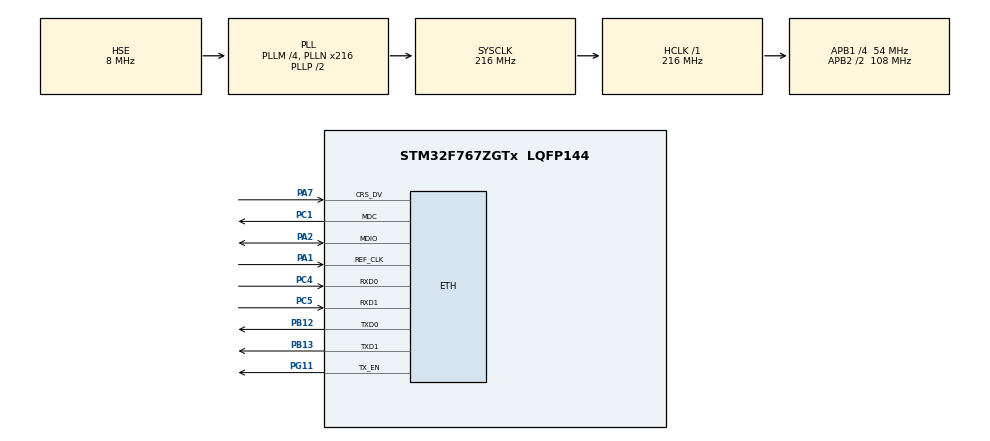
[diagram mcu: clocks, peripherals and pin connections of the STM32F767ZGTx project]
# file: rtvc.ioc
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ETH.MediaInterface=HAL_ETH_RMII_MODE
FREERTOS.Tasks01=defaultTask,0,512,StartDefaultTask,Default,NULL,Dynamic,NULL,NULL
FREERTOS.configMINIMAL_STACK_SIZE=512
LWIP.BSP.number=1
LWIP.GATEWAY_ADDRESS=010.000.000.050
LWIP.IP_ADDRESS=010.000.000.015
LWIP.LWIP_DHCP=0
LWIP.LWIP_RAM_HEAP_POINTER=0x20044000
LWIP.MEMP_NUM_TCP_SEG=17
LWIP.MEM_SIZE=16360
LWIP.NETMASK_ADDRESS=255.255.255.000
LWIP.TCP_MSS=1460
LWIP.TCP_SND_BUF=5840
LWIP.Version=v2.1.2_Cube
LWIP0.BSP.STBoard=false
LWIP0.BSP.api=BSP_COMPONENT_DRIVER
LWIP0.BSP.component=LAN8742
LWIP0.BSP.instance=LAN8742
LWIP0.BSP.name=Driver_PHY
LWIP0.BSP.semaphore=S_LAN8742
LWIP0.BSP.solution=LAN8742
Mcu.Family=STM32F7
Mcu.Name=STM32F767ZGTx
Mcu.Package=LQFP144
NVIC.ETH_IRQn=true\:5\:0\:false\:false\:true\:true\:false\:true\:true
NVIC.PriorityGroup=NVIC_PRIORITYGROUP_4
NVIC.TIM3_IRQn=true\:15\:0\:false\:false\:true\:false\:false\:true\:true
NVIC.TimeBase=TIM3_IRQn
NVIC.TimeBaseIP=TIM3
PA1.Mode=RMII
PA1.Signal=ETH_REF_CLK
PA13.Mode=JTAG_4_pins
PA13.Signal=SYS_JTMS-SWDIO
PA14.Mode=JTAG_4_pins
PA14.Signal=SYS_JTCK-SWCLK
PA15.Mode=JTAG_4_pins
PA15.Signal=SYS_JTDI
PA2.Mode=RMII
PA2.Signal=ETH_MDIO
PA7.Mode=RMII
PA7.Signal=ETH_CRS_DV
PB12.Mode=RMII
PB12.Signal=ETH_TXD0
PB13.Mode=RMII
PB13.Signal=ETH_TXD1
PB3.Mode=JTAG_4_pins
PB3.Signal=SYS_JTDO-SWO
PC1.Mode=RMII
PC1.Signal=ETH_MDC
PC4.Mode=RMII
PC4.Signal=ETH_RXD0
PC5.Mode=RMII
PC5.Signal=ETH_RXD1
PG11.Mode=RMII
PG11.Signal=ETH_TX_EN
PH0/OSC_IN.Mode=HSE-External-Oscillator
PH0/OSC_IN.Signal=RCC_OSC_IN
PH1/OSC_OUT.Mode=HSE-External-Oscillator
PH1/OSC_OUT.Signal=RCC_OSC_OUT
ProjectManager.HeapSize=0x200
ProjectManager.StackSize=0x400
ProjectManager.TargetToolchain=STM32CubeIDE
RCC.AHBFreq_Value=216000000
RCC.APB1CLKDivider=RCC_HCLK_DIV4
RCC.APB1Freq_Value=54000000
RCC.APB1TimFreq_Value=108000000
RCC.APB2CLKDivider=RCC_HCLK_DIV2
RCC.APB2Freq_Value=108000000
RCC.APB2TimFreq_Value=216000000
RCC.CortexFreq_Value=216000000
RCC.HCLKFreq_Value=216000000
RCC.HSE_VALUE=8000000
RCC.HSI_VALUE=16000000
RCC.LSE_VALUE=32768
RCC.PLLM=4
RCC.PLLN=216
RCC.PLLSourceVirtual=RCC_PLLSOURCE_HSE
RCC.SYSCLKFreq_VALUE=216000000
RCC.SYSCLKSource=RCC_SYSCLKSOURCE_PLLCLK
RCC.USBFreq_Value=216000000
RCC.VCOOutputFreq_Value=432000000
VP_FREERTOS_VS_CMSIS_V1.Mode=CMSIS_V1
VP_LWIP_VS_Enabled.Mode=Enabled
VP_SYS_VS_tim3.Mode=TIM3
board=custom

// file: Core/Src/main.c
/* USER CODE BEGIN Header */
/**
  ******************************************************************************
  * @file           : main.c
  * @brief          : Main program body
  ******************************************************************************
  * @attention
  *
  * Copyright (c) 2025 STMicroelectronics.
  * All rights reserved.
  *
  * This software is licensed under terms that can be found in the LICENSE file
  * in the root directory of this software component.
  * If no LICENSE file comes with this software, it is provided AS-IS.
  *
  ******************************************************************************
  */
/* USER CODE END Header */
#include "main.h"
#include "cmsis_os.h"
#include "lwip.h"

/* USER CODE BEGIN Includes */
#include "lan8742.h"
/* USER CODE END Includes */

osThreadId defaultTaskHandle;

void SystemClock_Config(void);
static void MX_GPIO_Init(void);
void StartDefaultTask(void const * argument);

int main(void)
{

  /* MCU Configuration--------------------------------------------------------*/

  /* Reset of all peripherals, Initializes the Flash interface and the Systick. */
  HAL_Init();

  /* Configure the system clock */
  SystemClock_Config();

  /* Initialize all configured peripherals */
  MX_GPIO_Init();

  /* Create the thread(s) */
  /* definition and creation of defaultTask */
  osThreadDef(defaultTask, StartDefaultTask, osPriorityNormal, 0, 512);
  defaultTaskHandle = osThreadCreate(osThread(defaultTask), NULL);

  /* Start scheduler */
  osKernelStart();

  /* We should never get here as control is now taken by the scheduler */

  /* Infinite loop */
  while (1)
  {

  }
}

void SystemClock_Config(void)
{
  RCC_OscInitTypeDef RCC_OscInitStruct = {0};
  RCC_ClkInitTypeDef RCC_ClkInitStruct = {0};

  /** Configure the main internal regulator output voltage
  */
  __HAL_RCC_PWR_CLK_ENABLE();
  __HAL_PWR_VOLTAGESCALING_CONFIG(PWR_REGULATOR_VOLTAGE_SCALE1);

  /** Initializes the RCC Oscillators according to the specified parameters
  * in the RCC_OscInitTypeDef structure.
  */
  RCC_OscInitStruct.OscillatorType = RCC_OSCILLATORTYPE_HSE;
  RCC_OscInitStruct.HSEState = RCC_HSE_ON;
  RCC_OscInitStruct.PLL.PLLState = RCC_PLL_ON;
  RCC_OscInitStruct.PLL.PLLSource = RCC_PLLSOURCE_HSE;
  RCC_OscInitStruct.PLL.PLLM = 4;
  RCC_OscInitStruct.PLL.PLLN = 216;
  RCC_OscInitStruct.PLL.PLLP = RCC_PLLP_DIV2;
  RCC_OscInitStruct.PLL.PLLQ = 2;
  RCC_OscInitStruct.PLL.PLLR = 2;
  if (HAL_RCC_OscConfig(&RCC_OscInitStruct) != HAL_OK)
  {
    Error_Handler();
  }

  /** Activate the Over-Drive mode
  */
  if (HAL_PWREx_EnableOverDrive() != HAL_OK)
  {
    Error_Handler();
  }

  /** Initializes the CPU, AHB and APB buses clocks
  */
  RCC_ClkInitStruct.ClockType = RCC_CLOCKTYPE_HCLK|RCC_CLOCKTYPE_SYSCLK
                              |RCC_CLOCKTYPE_PCLK1|RCC_CLOCKTYPE_PCLK2;
  RCC_ClkInitStruct.SYSCLKSource = RCC_SYSCLKSOURCE_PLLCLK;
  RCC_ClkInitStruct.AHBCLKDivider = RCC_SYSCLK_DIV1;
  RCC_ClkInitStruct.APB1CLKDivider = RCC_HCLK_DIV4;
  RCC_ClkInitStruct.APB2CLKDivider = RCC_HCLK_DIV2;

  if (HAL_RCC_ClockConfig(&RCC_ClkInitStruct, FLASH_LATENCY_7) != HAL_OK)
  {
    Error_Handler();
  }
}

static void MX_GPIO_Init(void)
{

  /* GPIO Ports Clock Enable */
  __HAL_RCC_GPIOH_CLK_ENABLE();
  __HAL_RCC_GPIOC_CLK_ENABLE();
  __HAL_RCC_GPIOA_CLK_ENABLE();
  __HAL_RCC_GPIOB_CLK_ENABLE();
  __HAL_RCC_GPIOG_CLK_ENABLE();

}

void StartDefaultTask(void const * argument)
{
  /* init code for LWIP */
  MX_LWIP_Init();
  /* USER CODE BEGIN 5 */
  /* Infinite loop */
  for(;;)
  {
    volatile int32_t status = LAN8742_GetLinkState(&LAN8742);
    osDelay(1000);
  }
  /* USER CODE END 5 */
}

void HAL_TIM_PeriodElapsedCallback(TIM_HandleTypeDef *htim)
{
  if (htim->Instance == TIM3) {
    HAL_IncTick();
  }
}

void Error_Handler(void)
{
  __disable_irq();
  while (1)
  {
  }
}

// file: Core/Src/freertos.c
/* USER CODE BEGIN Header */
/**
  ******************************************************************************
  * File Name          : freertos.c
  * Description        : Code for freertos applications
  ******************************************************************************
  * @attention
  *
  * Copyright (c) 2025 STMicroelectronics.
  * All rights reserved.
  *
  * This software is licensed under terms that can be found in the LICENSE file
  * in the root directory of this software component.
  * If no LICENSE file comes with this software, it is provided AS-IS.
  *
  ******************************************************************************
  */
/* USER CODE END Header */

#include "FreeRTOS.h"
#include "task.h"
#include "main.h"

/* GetIdleTaskMemory prototype (linked to static allocation support) */
void vApplicationGetIdleTaskMemory( StaticTask_t **ppxIdleTaskTCBBuffer, StackType_t **ppxIdleTaskStackBuffer, uint32_t *pulIdleTaskStackSize );

/* USER CODE BEGIN GET_IDLE_TASK_MEMORY */
static StaticTask_t xIdleTaskTCBBuffer;
static StackType_t xIdleStack[configMINIMAL_STACK_SIZE];

void vApplicationGetIdleTaskMemory( StaticTask_t **ppxIdleTaskTCBBuffer, StackType_t **ppxIdleTaskStackBuffer, uint32_t *pulIdleTaskStackSize )
{
  *ppxIdleTaskTCBBuffer = &xIdleTaskTCBBuffer;
  *ppxIdleTaskStackBuffer = &xIdleStack[0];
  *pulIdleTaskStackSize = configMINIMAL_STACK_SIZE;
  /* place for user code */
}
/* USER CODE END GET_IDLE_TASK_MEMORY */
